# moonlight_application register map
Vendor: Nordic Semiconductor; Series: lumos; File version: 1
CPU: CM33 r0p4, little endian, MPU, FPU, 3 interrupt priority bits, 176 interrupts, 4 SAU regions
Registers are 32-bit, read-write, reset 0x0 unless marked. A register's access mark holds for its fields unless they carry their own. Offsets are from the block's base; [hi:lo] are bit positions; lines under a group give offsets from that group; {n}, {i} and the like mark numbered series; 'fields as' and 'values as' point back to an identical list.

## ICACHE_S — Cache
Base 0xE0082000
0x00 TASKS_SAVE wo — Save the cache state to a retained memory space.
  [0] TASKS_SAVE
    1=Trigger task
0x04 TASKS_RESTORE wo — Restore the cache state from a retained memory space.
  [0] TASKS_RESTORE
    1=Trigger task
0x08 TASKS_INVALIDATECACHE wo — Invalidate the cache.
  [0] TASKS_INVALIDATECACHE
    1=Trigger task
0x14 TASKS_INVALIDATELINE wo — Invalidate the line.
  [0] TASKS_INVALIDATELINE
    1=Trigger task
0x20 TASKS_ERASE wo — Erase the cache.
  [0] TASKS_ERASE
    1=Trigger task
0x100 EVENTS_DONE — Save or Restore task is done.
  [0] EVENTS_DONE
    0=NotGenerated (Event not generated); 1=Generated (Event generated)
0x400 STATUS ro — Status of the cache activities.
  [0] READY — Ready status.
    0=Ready (Activity is done and ready for the next activity.); 1=Busy (Activity is in progress.)
0x404 ENABLE — Enable cache.
  [0] ENABLE — Enable cache
    0=Disabled (Disable cache); 1=Enabled (Enable cache)
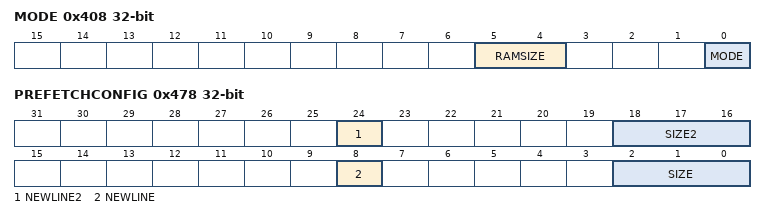
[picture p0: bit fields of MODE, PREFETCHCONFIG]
0x408 MODE — Cache mode.
  [5:4] RAMSIZE
    0=All (All RAM is used for cache memory); 1=Half of the RAM is used for cache memory; 2=Quarter of the RAM is used for cache memory; 3=None of the RAM is used for cache memory
  [0] MODE — Cache mode
    0=Cache mode; 1=Ram (RAM mode)
0x410 LINEADDR — Memory address covered by the line to be maintained.
  [31:0] ADDR — Address.
0x414 PROFILING group — Unspecified
  0x00 ENABLE — Enable the profiling counters.
    [0] ENABLE — Enable the profiling counters
      0=Disable profiling; 1=Enable profiling
  0x04 CLEAR wo — Clear the profiling counters.
    [0] CLEAR — Clearing the profiling counters
      1=Clear the profiling counters
  0x08 HIT ro — The cache hit counter for cache region.
    [31:0] HITS — Number of cache hits
  0x0C MISS ro — The cache miss counter for cache region.
    [31:0] MISSES — Number of cache misses
  0x10 LMISS ro — The cache line miss counter for cache region.
    [31:0] LMISSES — Number of cache line misses
  0x14 READS ro — Number of reads for cache region.
  0x18 WRITES ro — Number of writes for cache region.
0x430 DEBUGLOCK rw-once — Lock debug mode.
  [0] DEBUGLOCK — Lock debug mode
    0=Unlocked (Debug mode unlocked); 1=Locked (Debug mode locked. Ignores any other value written.)
0x434 WRITELOCK — Lock cache updates.
  [0] WRITELOCK — Lock cache updates
    0=Unlocked (Cache updates unlocked); 1=Locked (Cache updates locked)
0x478 PREFETCHCONFIG — Prefetch Policy.
  [24] NEWLINE2 — Allow speculative prefetch continue onto a new line.
    0=Disabled (Speculative prefetch continue onto a new line is disabled); 1=Enabled (Speculative prefetch continue onto a new line is enabled)
  [18:16] SIZE2 — Prefetch size 2
  [8] NEWLINE — Allow speculative prefetch continue onto a new line.
    values as NEWLINE2
  [2:0] SIZE — Prefetch size

## SWI00_S — Software interrupt 0
Base 0x5001C000
Same registers: SWI01_S 0x5001D000, SWI02_S 0x5001E000, SWI03_S 0x5001F000

## GLOBAL_DPPIC00_NS — Distributed programmable peripheral interconnect controller 0
Base 0x40042000
Same registers: GLOBAL_DPPIC10_NS 0x40082000, GLOBAL_DPPIC20_NS 0x400C2000, GLOBAL_DPPIC30_NS 0x40102000, GLOBAL_DPPIC00_S 0x50042000, GLOBAL_DPPIC10_S 0x50082000, GLOBAL_DPPIC20_S 0x500C2000, GLOBAL_DPPIC30_S 0x50102000
{0x0+8i} TASKS_CHG[{i}] (i=0..5) group — Channel group tasks
  0x00 EN wo — Description cluster: Enable channel group n
    [0] EN — Enable channel group n
      1=Trigger task
  0x04 DIS wo — Description cluster: Disable channel group n
    [0] DIS — Disable channel group n
      1=Trigger task
{0x80+8i} SUBSCRIBE_CHG[{i}] (i=0..5) group — Subscribe configuration for tasks
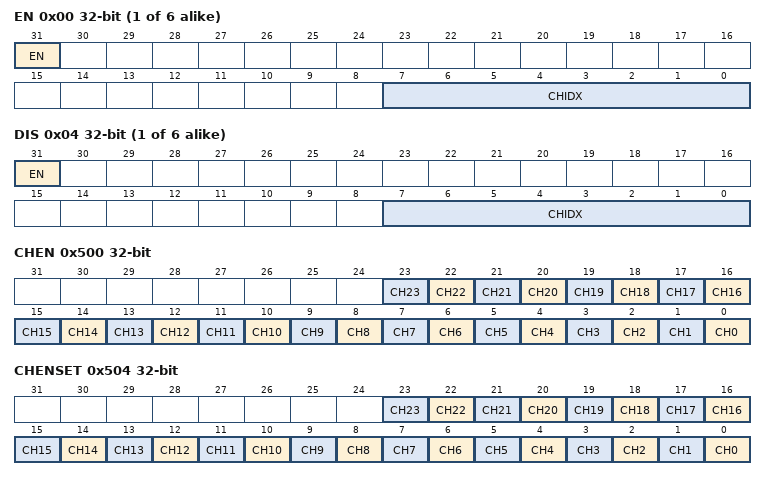
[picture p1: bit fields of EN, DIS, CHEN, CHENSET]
  0x00 EN — Description cluster: Subscribe configuration for task CHG[n].EN
    [31] EN
      0=Disabled (Disable subscription); 1=Enabled (Enable subscription)
    [7:0] CHIDX — DPPI channel that task CHG[n].EN will subscribe to
  0x04 DIS — Description cluster: Subscribe configuration for task CHG[n].DIS
    [31] EN
      values as SUBSCRIBE_CHG[0].EN.EN
    [7:0] CHIDX — DPPI channel that task CHG[n].DIS will subscribe to
0x500 CHEN — Channel enable register
  [all] fields
    0=Disabled (Disable channel); 1=Enabled (Enable channel)
  [n] CH{n} (n=0..23) — Enable or disable channel {n}
0x504 CHENSET write-1-sets — Channel enable set register
  [all] fields
    on read: 0=Disabled (Read: Channel disabled); 1=Enabled (Read: Channel enabled) | on write: 1=Set (Write: Enable channel)
  [n] CH{n} (n=0..23) — Channel {n} enable set register. Writing 0 has no effect.
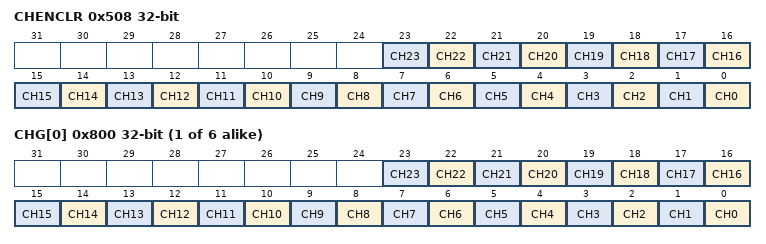
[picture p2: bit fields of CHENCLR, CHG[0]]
0x508 CHENCLR write-1-clears — Channel enable clear register
  [all] fields
    on read: 0=Disabled (Read: Channel disabled); 1=Enabled (Read: Channel enabled) | on write: 1=Clear (Write: Disable channel)
  [n] CH{n} (n=0..23) — Channel {n} enable clear register. Writing 0 has no effect.
{0x800+4i} CHG[{i}] (i=0..5) — Description collection: Channel group n Note: Writes to this register are ignored if either SUBSCRIBE_CHG[n].EN or SUBSCRIBE_CHG[n].DIS is enabled
  [all] fields
    0=Excluded; 1=Included
  [n] CH{n} (n=0..23) — Include or exclude channel {n}
